# STM32F479 register map
File version: 2.0
CPU: CM4 r0p1, little endian, MPU, FPU, 4 interrupt priority bits
Registers are 32-bit, read-write, reset 0x0 unless marked. A register's access mark holds for its fields unless they carry their own. Offsets are from the block's base; [hi:lo] are bit positions; lines under a group give offsets from that group; {n}, {i} and the like mark numbered series.

## ADC1 — Analog-to-digital converter
Base 0x40012000
Same registers: ADC2 0x40012100, ADC3 0x40012200
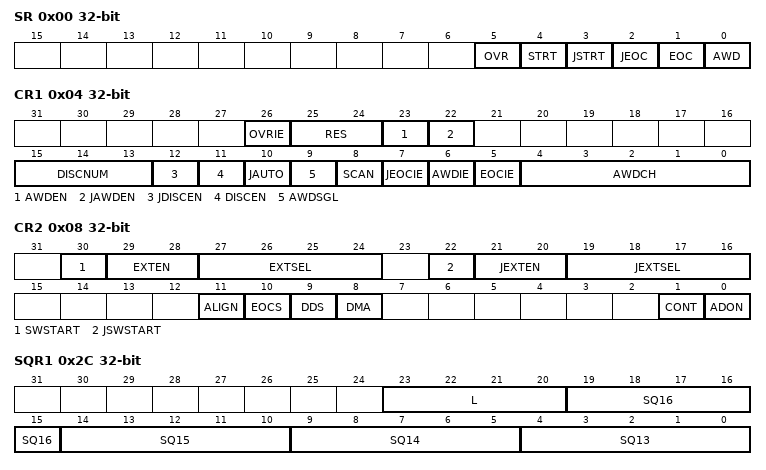
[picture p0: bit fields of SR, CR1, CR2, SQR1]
0x00 SR — status register
  [5] OVR — Overrun
  [4] STRT — Regular channel start flag
  [3] JSTRT — Injected channel start flag
  [2] JEOC — Injected channel end of conversion
  [1] EOC — Regular channel end of conversion
  [0] AWD — Analog watchdog flag
0x04 CR1 — control register 1
  [26] OVRIE — Overrun interrupt enable
  [25:24] RES — Resolution
  [23] AWDEN — Analog watchdog enable on regular channels
  [22] JAWDEN — Analog watchdog enable on injected channels
  [15:13] DISCNUM — Discontinuous mode channel count
  [12] JDISCEN — Discontinuous mode on injected channels
  [11] DISCEN — Discontinuous mode on regular channels
  [10] JAUTO — Automatic injected group conversion
  [9] AWDSGL — Enable the watchdog on a single channel in scan mode
  [8] SCAN — Scan mode
  [7] JEOCIE — Interrupt enable for injected channels
  [6] AWDIE — Analog watchdog interrupt enable
  [5] EOCIE — Interrupt enable for EOC
  [4:0] AWDCH — Analog watchdog channel select bits
0x08 CR2 — control register 2
  [30] SWSTART — Start conversion of regular channels
  [29:28] EXTEN — External trigger enable for regular channels
  [27:24] EXTSEL — External event select for regular group
  [22] JSWSTART — Start conversion of injected channels
  [21:20] JEXTEN — External trigger enable for injected channels
  [19:16] JEXTSEL — External event select for injected group
  [11] ALIGN — Data alignment
  [10] EOCS — End of conversion selection
  [9] DDS — DMA disable selection (for single ADC mode)
  [8] DMA — Direct memory access mode (for single ADC mode)
  [1] CONT — Continuous conversion
  [0] ADON — A/D Converter ON / OFF
0x0C SMPR1 — sample time register 1
  [31:0] SMPx_x — Sample time bits
0x10 SMPR2 — sample time register 2
  [31:0] SMPx_x — Sample time bits
{0x10+4i} JOFR{i} (i=1..4) — injected channel data offset register x
  [11:0] JOFFSET{i} — Data offset for injected channel x
0x24 HTR reset 0xFFF — watchdog higher threshold register
  [11:0] HT — Analog watchdog higher threshold
0x28 LTR — watchdog lower threshold register
  [11:0] LT — Analog watchdog lower threshold
0x2C SQR1 — regular sequence register 1
  [23:20] L — Regular channel sequence length
  [5n-61:5n-65] SQ{n} (n=13..16) — {n}th conversion in regular sequence
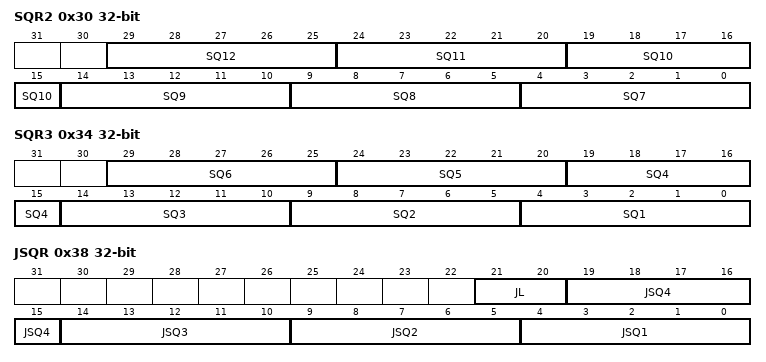
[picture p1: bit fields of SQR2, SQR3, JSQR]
0x30 SQR2 — regular sequence register 2
  [5n-31:5n-35] SQ{n} (n=7..12) — {n}th conversion in regular sequence
0x34 SQR3 — regular sequence register 3
  [29:25] SQ6 — 6th conversion in regular sequence
  [24:20] SQ5 — 5th conversion in regular sequence
  [19:15] SQ4 — 4th conversion in regular sequence
  [14:10] SQ3 — 3rd conversion in regular sequence
  [9:5] SQ2 — 2nd conversion in regular sequence
  [4:0] SQ1 — 1st conversion in regular sequence
0x38 JSQR — injected sequence register
  [21:20] JL — Injected sequence length
  [19:15] JSQ4 — 4th conversion in injected sequence
  [14:10] JSQ3 — 3rd conversion in injected sequence
  [9:5] JSQ2 — 2nd conversion in injected sequence
  [4:0] JSQ1 — 1st conversion in injected sequence
{0x38+4i} JDR{i} ro (i=1..4) — injected data register x
  [15:0] JDATA — Injected data
0x4C DR ro — regular data register
  [15:0] DATA — Regular data

## CRC — Cryptographic processor
Base 0x40023000
0x00 DR reset 0xFFFFFFFF — Data register
  [31:0] DR — Data Register
0x04 IDR — Independent Data register
  [7:0] IDR
0x08 CR wo — Control register
  [0] CR — Control regidter

## CRYP — Cryptographic processor
Base 0x50060000
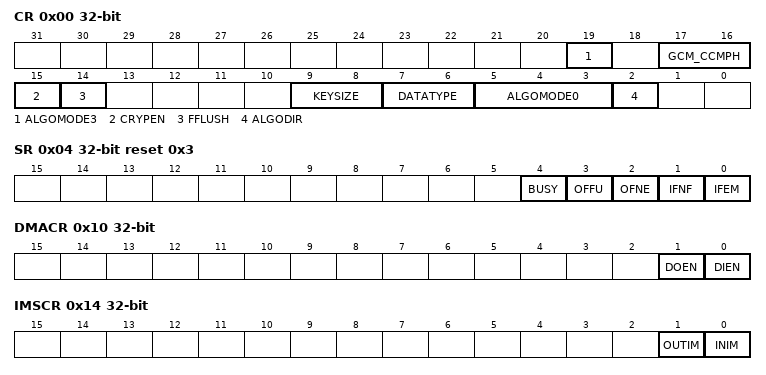
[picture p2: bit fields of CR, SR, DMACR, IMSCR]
0x00 CR access per field — control register
  [19] ALGOMODE3 rw — ALGOMODE
  [17:16] GCM_CCMPH rw
  [15] CRYPEN rw — Cryptographic processor enable
  [14] FFLUSH wo — FIFO flush
  [9:8] KEYSIZE rw — Key size selection (AES mode only)
  [7:6] DATATYPE rw — Data type selection
  [5:3] ALGOMODE0 rw — Algorithm mode
  [2] ALGODIR rw — Algorithm direction
0x04 SR ro reset 0x3 — status register
  [4] BUSY — Busy bit
  [3] OFFU — Output FIFO full
  [2] OFNE — Output FIFO not empty
  [1] IFNF — Input FIFO not full
  [0] IFEM — Input FIFO empty
0x08 DIN — data input register
  [31:0] DATAIN — Data input
0x0C DOUT ro — data output register
  [31:0] DATAOUT — Data output
0x10 DMACR — DMA control register
  [1] DOEN — DMA output enable
  [0] DIEN — DMA input enable
0x14 IMSCR — interrupt mask set/clear register
  [1] OUTIM — Output FIFO service interrupt mask
  [0] INIM — Input FIFO service interrupt mask
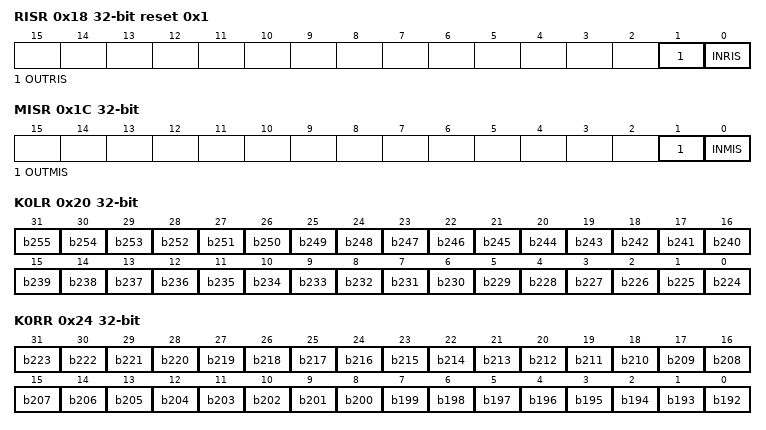
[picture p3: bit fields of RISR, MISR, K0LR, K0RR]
0x18 RISR ro reset 0x1 — raw interrupt status register
  [1] OUTRIS — Output FIFO service raw interrupt status
  [0] INRIS — Input FIFO service raw interrupt status
0x1C MISR ro — masked interrupt status register
  [1] OUTMIS — Output FIFO service masked interrupt status
  [0] INMIS — Input FIFO service masked interrupt status
0x20 K0LR wo — key registers
  [n-224] b{n} (n=224..255)
0x24 K0RR wo — key registers
  [n-192] b{n} (n=192..223)
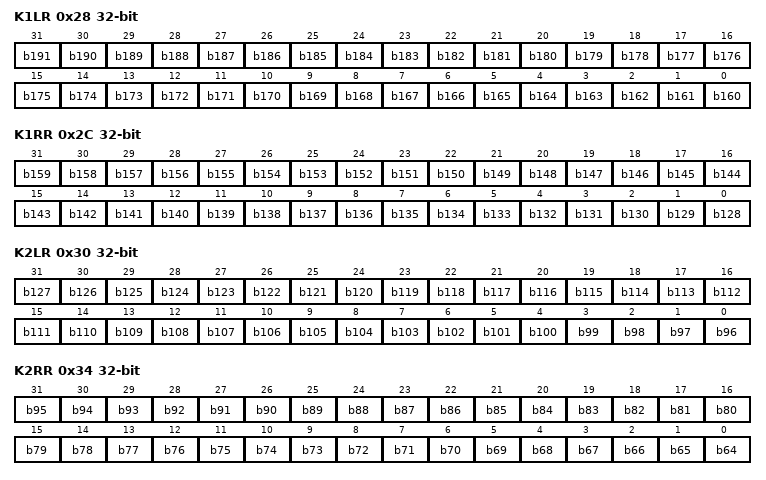
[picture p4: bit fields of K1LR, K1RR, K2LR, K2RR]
0x28 K1LR wo — key registers
  [n-160] b{n} (n=160..191)
0x2C K1RR wo — key registers
  [n-128] b{n} (n=128..159)
0x30 K2LR wo — key registers
  [n-96] b{n} (n=96..127)
0x34 K2RR wo — key registers
  [n-64] b{n} (n=64..95)
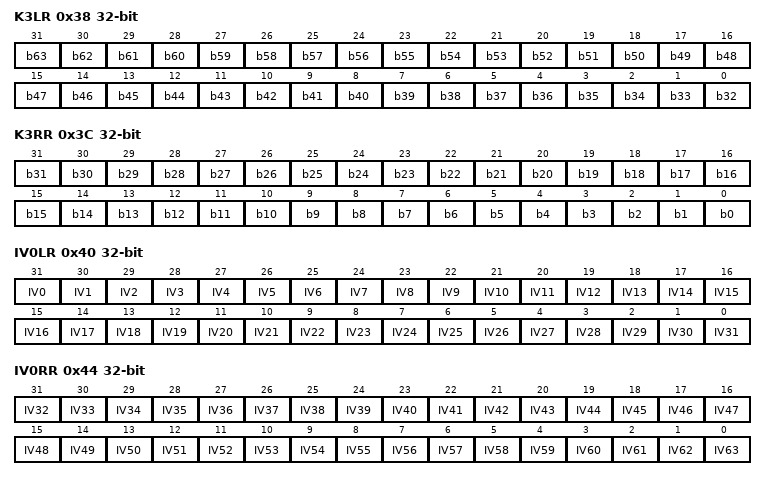
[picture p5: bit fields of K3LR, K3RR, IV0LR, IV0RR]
0x38 K3LR wo — key registers
  [n-32] b{n} (n=32..63)
0x3C K3RR wo — key registers
  [n] b{n} (n=0..31)
0x40 IV0LR — initialization vector registers
  [31-n] IV{n} (n=0..31)
0x44 IV0RR — initialization vector registers
  [63-n] IV{n} (n=32..63)
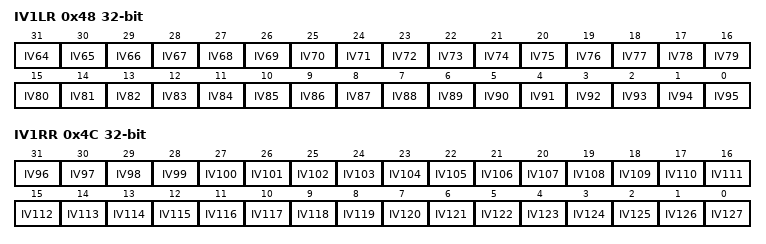
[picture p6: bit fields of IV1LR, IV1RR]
0x48 IV1LR — initialization vector registers
  [95-n] IV{n} (n=64..95)
0x4C IV1RR — initialization vector registers
  [127-n] IV{n} (n=96..127)
{0x50+4i} CSGCMCCM{i}R (i=0..7) — context swap register
{0x70+4i} CSGCM{i}R (i=0..7) — context swap register

## Notices in the file
Copyright (c) 2024 STMicroelectronics.
SPDX-License-Identifier: Apache-2.0
Licensed under the Apache License, Version 2.0 (the "License");
you may not use this file except in compliance with the License.
You may obtain a copy of the License at
http://www.apache.org/licenses/LICENSE-2.0
Unless required by applicable law or agreed to in writing, software
distributed under the License is distributed on an "AS IS" BASIS,
WITHOUT WARRANTIES OR CONDITIONS OF ANY KIND, either express or implied.
See the License for the specific language governing permissions and
limitations under the License.
